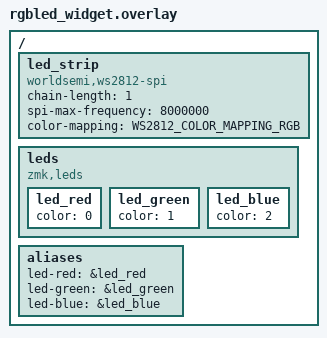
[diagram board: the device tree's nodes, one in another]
/ {
    led_strip: led_strip {
        compatible = "worldsemi,ws2812-spi";
        chain-length = <1>;
        spi-max-frequency = <8000000>;
        color-mapping = <WS2812_COLOR_MAPPING_RGB>;
        status = "okay";
    };

    leds {
        compatible = "zmk,leds";

        led_red: led_red {
            color = <0>;
        };

        led_green: led_green {
            color = <1>;
        };

        led_blue: led_blue {
            color = <2>;
        };
    };

    aliases {
        led-red = &led_red;
        led-green = &led_green;
        led-blue = &led_blue;
    };
};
